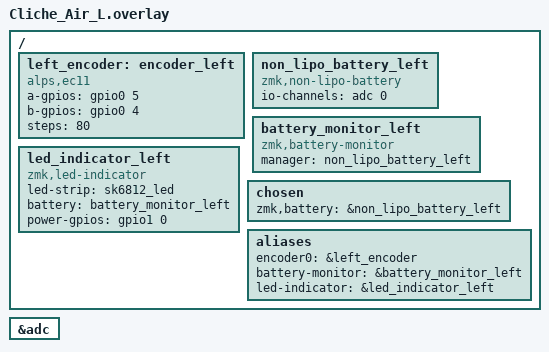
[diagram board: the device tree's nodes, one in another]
#include "Cliche_Air.dtsi"
#include <input/processors.dtsi>

/ {
    /* 左手: Central（エンコーダ・バッテリモニタ・LED） */

    /* 左用エンコーダ有効 */
    left_encoder: encoder_left {
        compatible = "alps,ec11";
        a-gpios = <&gpio0 5 (GPIO_ACTIVE_HIGH | GPIO_PULL_UP)>; /* ENC_A -> P0.05 */
        b-gpios = <&gpio0 4 (GPIO_ACTIVE_HIGH | GPIO_PULL_UP)>; /* ENC_B -> P0.04 */
        steps = <80>;
        status = "okay";
    };

    /* Non-LiPo バッテリ（左）：io-channels は saadc の channel を参照 */
    non_lipo_battery_left: non_lipo_battery_left {
        compatible = "zmk,non-lipo-battery";
        io-channels = <&adc 0>;
        status = "okay";
    };

    battery_monitor_left: battery_monitor_left {
        compatible = "zmk,battery-monitor";
        manager = <&non_lipo_battery_left>;
        status = "okay";
    };

    /* 左の LED 指示器は共通 sk6812_led を有効化して使う */
    led_indicator_left: led_indicator_left {
        compatible = "zmk,led-indicator";
        led-strip = <&sk6812_led>;
        battery = <&battery_monitor_left>;
        power-gpios = <&gpio1 0 GPIO_ACTIVE_HIGH>; /* LED_EN -> P1.00 */
        status = "okay";
    };

    chosen {
        zmk,battery = &non_lipo_battery_left;
    };

    aliases {
        encoder0 = &left_encoder;
        battery-monitor = &battery_monitor_left;
        led-indicator = &led_indicator_left;
    };
};

/* 左（Central）側で ADC 有効化のみ（チャンネル構成は内部で管理） */
&adc {
    status = "okay";
};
